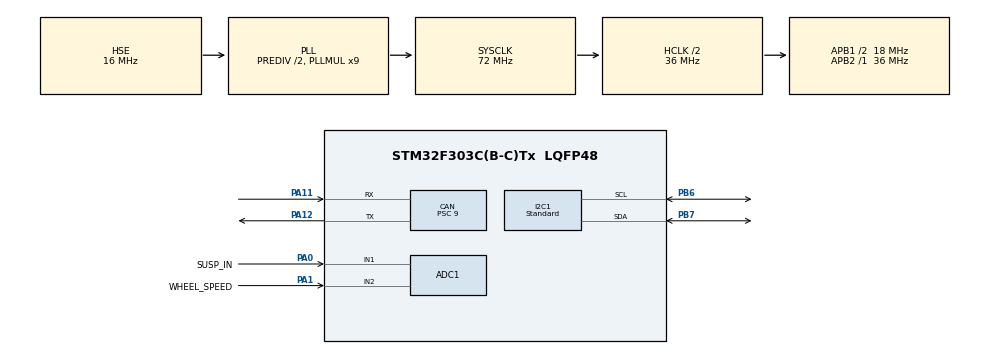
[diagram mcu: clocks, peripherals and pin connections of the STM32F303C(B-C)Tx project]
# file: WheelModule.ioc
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ADC1.Channel-4\#ChannelRegularConversion=ADC_CHANNEL_1
ADC1.Channel-5\#ChannelRegularConversion=ADC_CHANNEL_2
ADC1.ClockPrescaler=ADC_CLOCK_ASYNC_DIV1
ADC1.ContinuousConvMode=ENABLE
ADC1.DMAContinuousRequests=ENABLE
ADC1.NbrOfConversion=2
ADC1.NbrOfConversionFlag=1
ADC1.Offset-4\#ChannelRegularConversion=0
ADC1.Offset-5\#ChannelRegularConversion=0
ADC1.OffsetNumber-4\#ChannelRegularConversion=ADC_OFFSET_NONE
ADC1.OffsetNumber-5\#ChannelRegularConversion=ADC_OFFSET_NONE
ADC1.Rank-4\#ChannelRegularConversion=1
ADC1.Rank-5\#ChannelRegularConversion=2
ADC1.SamplingTime-4\#ChannelRegularConversion=ADC_SAMPLETIME_1CYCLE_5
ADC1.SamplingTime-5\#ChannelRegularConversion=ADC_SAMPLETIME_1CYCLE_5
ADC1.master=1
CAN.ABOM=ENABLE
CAN.BS1=CAN_BS1_6TQ
CAN.CalculateTimeQuantum=500.0
CAN.Prescaler=9
CAN.SJW=CAN_SJW_3TQ
Dma.ADC1.0.Direction=DMA_PERIPH_TO_MEMORY
Dma.ADC1.0.Instance=DMA1_Channel1
Dma.ADC1.0.MemDataAlignment=DMA_MDATAALIGN_HALFWORD
Dma.ADC1.0.MemInc=DMA_MINC_ENABLE
Dma.ADC1.0.Mode=DMA_CIRCULAR
Dma.ADC1.0.PeriphDataAlignment=DMA_PDATAALIGN_HALFWORD
Dma.ADC1.0.PeriphInc=DMA_PINC_DISABLE
Dma.ADC1.0.Priority=DMA_PRIORITY_MEDIUM
Dma.Request0=ADC1
I2C1.I2C_Speed_Mode=I2C_Standard
Mcu.Family=STM32F3
Mcu.Name=STM32F303C(B-C)Tx
Mcu.Package=LQFP48
NVIC.CAN_RX1_IRQn=true\:0\:0\:false\:false\:true\:true\:true
NVIC.CAN_SCE_IRQn=true\:0\:0\:false\:false\:true\:true\:true
NVIC.DMA1_Channel1_IRQn=true\:0\:0\:false\:false\:true\:false\:true
NVIC.I2C1_EV_IRQn=true\:0\:0\:false\:false\:true\:true\:true
NVIC.PriorityGroup=NVIC_PRIORITYGROUP_4
NVIC.TIM1_TRG_COM_TIM17_IRQn=true\:0\:0\:false\:false\:true\:true\:true
NVIC.USB_HP_CAN_TX_IRQn=true\:0\:0\:false\:false\:true\:true\:true
NVIC.USB_LP_CAN_RX0_IRQn=true\:0\:0\:false\:false\:true\:true\:true
PA0.GPIO_Label=SUSP_IN
PA0.Mode=IN1-Single-Ended
PA0.Signal=ADC1_IN1
PA1.GPIO_Label=WHEEL_SPEED
PA1.Mode=IN2-Single-Ended
PA1.Signal=ADC1_IN2
PA11.Mode=Master
PA11.Signal=CAN_RX
PA12.Mode=Master
PA12.Signal=CAN_TX
PA13.Mode=Serial_Wire
PA13.Signal=SYS_JTMS-SWDIO
PA14.Mode=Serial_Wire
PA14.Signal=SYS_JTCK-SWCLK
PB6.Mode=I2C
PB6.Signal=I2C1_SCL
PB7.Mode=I2C
PB7.Signal=I2C1_SDA
PF0-OSC_IN.Mode=HSE-External-Clock-Source
PF0-OSC_IN.Signal=RCC_OSC_IN
ProjectManager.HeapSize=0x200
ProjectManager.StackSize=0x400
ProjectManager.TargetToolchain=TrueSTUDIO
RCC.ADC12PRES=RCC_ADC12PLLCLK_DIV16
RCC.AHBCLKDivider=RCC_SYSCLK_DIV2
RCC.AHBFreq_Value=36000000
RCC.APB1CLKDivider=RCC_HCLK_DIV2
RCC.APB1Freq_Value=18000000
RCC.APB1TimFreq_Value=36000000
RCC.APB2Freq_Value=36000000
RCC.APB2TimFreq_Value=36000000
RCC.CortexFreq_Value=36000000
RCC.HCLKFreq_Value=36000000
RCC.HSE_VALUE=16000000
RCC.HSI_VALUE=8000000
RCC.LSE_VALUE=32768
RCC.PLLMUL=RCC_PLL_MUL9
RCC.PLLSourceVirtual=RCC_PLLSOURCE_HSE
RCC.RCC_PLLsource_Clock_Source_FROM_HSE=RCC_HSE_PREDIV_DIV2
RCC.SYSCLKFreq_VALUE=72000000
RCC.SYSCLKSourceVirtual=RCC_SYSCLKSOURCE_PLLCLK
RCC.USBFreq_Value=72000000
TIM17.ClockDivision=TIM_CLOCKDIVISION_DIV1
TIM17.Period=299
TIM17.Prescaler=9999
VP_TIM16_VS_ClockSourceINT.Mode=Enable_Timer
VP_TIM17_VS_ClockSourceINT.Mode=Enable_Timer
board=Dashboard

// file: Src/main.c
/* USER CODE BEGIN Header */
/**
  ******************************************************************************
  * @file           : main.c
  * @brief          : Main program body
  ******************************************************************************
  * @attention
  *
  * <h2><center>&copy; Copyright (c) 2019 STMicroelectronics.
  * All rights reserved.</center></h2>
  *
  * This software component is licensed by ST under BSD 3-Clause license,
  * the "License"; You may not use this file except in compliance with the
  * License. You may obtain a copy of the License at:
  *                        opensource.org/licenses/BSD-3-Clause
  *
  ******************************************************************************
  */
/* USER CODE END Header */

#include "main.h"
#include "adc.h"
#include "can.h"
#include "dma.h"
#include "i2c.h"
#include "tim.h"
#include "gpio.h"

/* USER CODE BEGIN Includes */
#include "m_task_manager.h"
/* USER CODE END Includes */

/* USER CODE BEGIN PV */
/* Private variables ---------------------------------------------------------*/

/* USER CODE END PV */

void SystemClock_Config(void);
/* USER CODE BEGIN PFP */
/* Private function prototypes -----------------------------------------------*/

/* USER CODE END PFP */

int main(void)
{

  /* MCU Configuration--------------------------------------------------------*/

  /* Reset of all peripherals, Initializes the Flash interface and the Systick. */
  HAL_Init();

  /* Configure the system clock */
  SystemClock_Config();

  /* Initialize all configured peripherals */
  MX_GPIO_Init();
  MX_DMA_Init();
  MX_CAN_Init();
  MX_TIM16_Init();
  MX_TIM17_Init();
  MX_ADC1_Init();
  MX_I2C1_Init();
  /* USER CODE BEGIN 2 */
  m_task_manager_init();
  return 1; /* Should never reach this point */
  /* USER CODE END 2 */

  /* Infinite loop */
  while (1)
  {

  }
}

void SystemClock_Config(void)
{
  RCC_OscInitTypeDef RCC_OscInitStruct = {0};
  RCC_ClkInitTypeDef RCC_ClkInitStruct = {0};
  RCC_PeriphCLKInitTypeDef PeriphClkInit = {0};

  /** Initializes the CPU, AHB and APB busses clocks
  */
  RCC_OscInitStruct.OscillatorType = RCC_OSCILLATORTYPE_HSI|RCC_OSCILLATORTYPE_HSE;
  RCC_OscInitStruct.HSEState = RCC_HSE_BYPASS;
  RCC_OscInitStruct.HSEPredivValue = RCC_HSE_PREDIV_DIV2;
  RCC_OscInitStruct.HSIState = RCC_HSI_ON;
  RCC_OscInitStruct.HSICalibrationValue = RCC_HSICALIBRATION_DEFAULT;
  RCC_OscInitStruct.PLL.PLLState = RCC_PLL_ON;
  RCC_OscInitStruct.PLL.PLLSource = RCC_PLLSOURCE_HSE;
  RCC_OscInitStruct.PLL.PLLMUL = RCC_PLL_MUL9;
  if (HAL_RCC_OscConfig(&RCC_OscInitStruct) != HAL_OK)
  {
    Error_Handler();
  }
  /** Initializes the CPU, AHB and APB busses clocks
  */
  RCC_ClkInitStruct.ClockType = RCC_CLOCKTYPE_HCLK|RCC_CLOCKTYPE_SYSCLK
                              |RCC_CLOCKTYPE_PCLK1|RCC_CLOCKTYPE_PCLK2;
  RCC_ClkInitStruct.SYSCLKSource = RCC_SYSCLKSOURCE_PLLCLK;
  RCC_ClkInitStruct.AHBCLKDivider = RCC_SYSCLK_DIV2;
  RCC_ClkInitStruct.APB1CLKDivider = RCC_HCLK_DIV2;
  RCC_ClkInitStruct.APB2CLKDivider = RCC_HCLK_DIV1;

  if (HAL_RCC_ClockConfig(&RCC_ClkInitStruct, FLASH_LATENCY_1) != HAL_OK)
  {
    Error_Handler();
  }
  PeriphClkInit.PeriphClockSelection = RCC_PERIPHCLK_I2C1|RCC_PERIPHCLK_ADC12;
  PeriphClkInit.Adc12ClockSelection = RCC_ADC12PLLCLK_DIV16;
  PeriphClkInit.I2c1ClockSelection = RCC_I2C1CLKSOURCE_HSI;
  if (HAL_RCCEx_PeriphCLKConfig(&PeriphClkInit) != HAL_OK)
  {
    Error_Handler();
  }
}

void Error_Handler(void)
{
  while(1)
  {
  }
}

/************************ (C) COPYRIGHT STMicroelectronics *****END OF FILE****/
